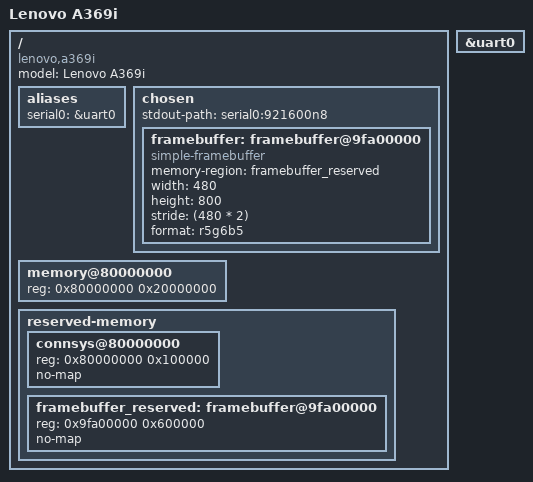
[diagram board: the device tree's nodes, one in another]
// SPDX-License-Identifier: GPL-2.0
/*
 * Copyright (c) 2025 Max Shevchenko <wctrl@proton.me>
 */

/dts-v1/;
#include "mt6572.dtsi"

/ {
	model = "Lenovo A369i";
	compatible = "lenovo,a369i", "mediatek,mt6572";

	aliases {
		serial0 = &uart0;
	};

	chosen {
		#address-cells = <1>;
		#size-cells = <1>;
		stdout-path = "serial0:921600n8";

		framebuffer: framebuffer@9fa00000 {
			compatible = "simple-framebuffer";
			memory-region = <&framebuffer_reserved>;
			width = <480>;
			height = <800>;
			stride = <(480 * 2)>;
			format = "r5g6b5";
		};
	};

	memory@80000000 {
		device_type = "memory";
		reg = <0x80000000 0x20000000>;
	};

	reserved-memory {
		#address-cells = <1>;
		#size-cells = <1>;
		ranges;

		connsys@80000000 {
			reg = <0x80000000 0x100000>;
			no-map;
		};

		framebuffer_reserved: framebuffer@9fa00000 {
			reg = <0x9fa00000 0x600000>;
			no-map;
		};
	};
};

&uart0 {
	status = "okay";
};
